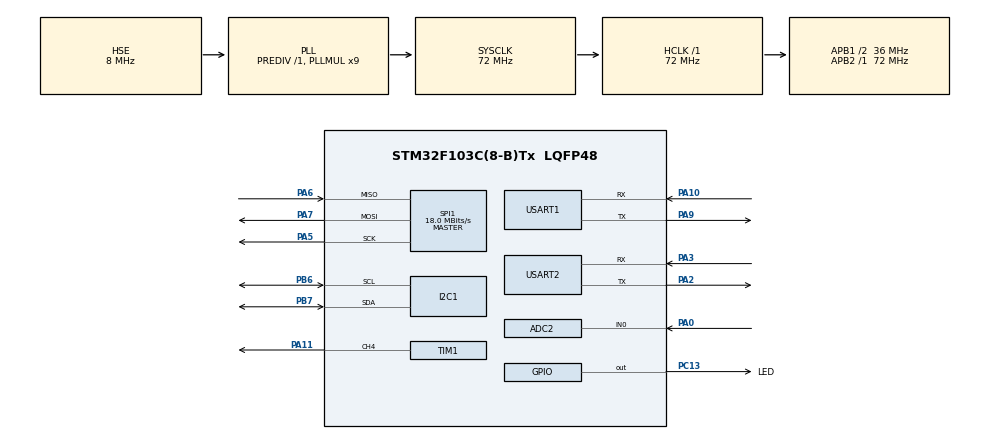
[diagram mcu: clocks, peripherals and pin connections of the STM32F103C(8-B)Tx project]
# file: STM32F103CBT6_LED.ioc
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ADC1.Channel-0\#ChannelRegularConversion=ADC_CHANNEL_TEMPSENSOR
ADC1.ContinuousConvMode=ENABLE
ADC1.NbrOfConversionFlag=1
ADC1.Rank-0\#ChannelRegularConversion=1
ADC1.SamplingTime-0\#ChannelRegularConversion=ADC_SAMPLETIME_239CYCLES_5
ADC1.master=1
ADC2.Channel-0\#ChannelRegularConversion=ADC_CHANNEL_0
ADC2.NbrOfConversionFlag=1
ADC2.Rank-0\#ChannelRegularConversion=1
ADC2.SamplingTime-0\#ChannelRegularConversion=ADC_SAMPLETIME_55CYCLES_5
Dma.MEMTOMEM.0.Direction=DMA_MEMORY_TO_MEMORY
Dma.MEMTOMEM.0.Instance=DMA1_Channel1
Dma.MEMTOMEM.0.MemDataAlignment=DMA_MDATAALIGN_BYTE
Dma.MEMTOMEM.0.MemInc=DMA_MINC_ENABLE
Dma.MEMTOMEM.0.Mode=DMA_NORMAL
Dma.MEMTOMEM.0.PeriphDataAlignment=DMA_PDATAALIGN_BYTE
Dma.MEMTOMEM.0.PeriphInc=DMA_PINC_ENABLE
Dma.MEMTOMEM.0.Priority=DMA_PRIORITY_LOW
Dma.Request0=MEMTOMEM
Dma.Request1=TIM1_CH4/TRIG/COM
Dma.TIM1_CH4/TRIG/COM.1.Direction=DMA_MEMORY_TO_PERIPH
Dma.TIM1_CH4/TRIG/COM.1.Instance=DMA1_Channel4
Dma.TIM1_CH4/TRIG/COM.1.MemDataAlignment=DMA_MDATAALIGN_WORD
Dma.TIM1_CH4/TRIG/COM.1.MemInc=DMA_MINC_ENABLE
Dma.TIM1_CH4/TRIG/COM.1.Mode=DMA_NORMAL
Dma.TIM1_CH4/TRIG/COM.1.PeriphDataAlignment=DMA_PDATAALIGN_WORD
Dma.TIM1_CH4/TRIG/COM.1.PeriphInc=DMA_PINC_DISABLE
Dma.TIM1_CH4/TRIG/COM.1.Priority=DMA_PRIORITY_LOW
IWDG.Prescaler=IWDG_PRESCALER_16
IWDG.Reload=2500-1
Mcu.Family=STM32F1
Mcu.Name=STM32F103C(8-B)Tx
Mcu.Package=LQFP48
NVIC.DMA1_Channel1_IRQn=true\:0\:0\:false\:false\:true\:true\:true\:true
NVIC.DMA1_Channel4_IRQn=true\:0\:0\:false\:false\:true\:false\:true\:true
NVIC.PriorityGroup=NVIC_PRIORITYGROUP_4
PA0-WKUP.Signal=ADCx_IN0
PA10.Mode=Asynchronous
PA10.Signal=USART1_RX
PA11.GPIO_Speed=GPIO_SPEED_FREQ_HIGH
PA11.Signal=S_TIM1_CH4
PA13.Mode=Trace_Asynchronous_SW
PA13.Signal=SYS_JTMS-SWDIO
PA14.Mode=Trace_Asynchronous_SW
PA14.Signal=SYS_JTCK-SWCLK
PA2.Mode=Asynchronous
PA2.Signal=USART2_TX
PA3.Mode=Asynchronous
PA3.Signal=USART2_RX
PA5.Mode=Full_Duplex_Master
PA5.Signal=SPI1_SCK
PA6.Mode=Full_Duplex_Master
PA6.Signal=SPI1_MISO
PA7.Mode=Full_Duplex_Master
PA7.Signal=SPI1_MOSI
PA9.Mode=Asynchronous
PA9.Signal=USART1_TX
PB3.Mode=Trace_Asynchronous_SW
PB3.Signal=SYS_JTDO-TRACESWO
PB6.Mode=I2C
PB6.Signal=I2C1_SCL
PB7.Mode=I2C
PB7.Signal=I2C1_SDA
PC13-TAMPER-RTC.GPIO_Label=LED
PC13-TAMPER-RTC.Signal=GPIO_Output
PD0-OSC_IN.Mode=HSE-External-Oscillator
PD0-OSC_IN.Signal=RCC_OSC_IN
PD1-OSC_OUT.Mode=HSE-External-Oscillator
PD1-OSC_OUT.Signal=RCC_OSC_OUT
ProjectManager.HeapSize=0x200
ProjectManager.StackSize=0x400
ProjectManager.TargetToolchain=STM32CubeIDE
RCC.ADCPresc=RCC_ADCPCLK2_DIV6
RCC.AHBFreq_Value=72000000
RCC.APB1CLKDivider=RCC_HCLK_DIV2
RCC.APB1Freq_Value=36000000
RCC.APB1TimFreq_Value=72000000
RCC.APB2Freq_Value=72000000
RCC.APB2TimFreq_Value=72000000
RCC.HCLKFreq_Value=72000000
RCC.PLLMUL=RCC_PLL_MUL9
RCC.PLLSourceVirtual=RCC_PLLSOURCE_HSE
RCC.SYSCLKFreq_VALUE=72000000
RCC.SYSCLKSource=RCC_SYSCLKSOURCE_PLLCLK
RCC.USBFreq_Value=72000000
SH.ADCx_IN0.0=ADC2_IN0,IN0
SH.S_TIM1_CH4.0=TIM1_CH4,PWM Generation4 CH4
SPI1.BaudRatePrescaler=SPI_BAUDRATEPRESCALER_4
SPI1.CalculateBaudRate=18.0 MBits/s
SPI1.Direction=SPI_DIRECTION_2LINES
SPI1.Mode=SPI_MODE_MASTER
SPI1.VirtualType=VM_MASTER
TIM1.Channel-PWM\ Generation4\ CH4=TIM_CHANNEL_4
TIM1.Period=90-1
TIM1.Prescaler=0
TIM3.Prescaler=72-1
USART1.VirtualMode=VM_ASYNC
USART2.VirtualMode=VM_ASYNC
VP_ADC1_TempSens_Input.Mode=IN-TempSens
VP_CRC_VS_CRC.Mode=CRC_Activate
VP_IWDG_VS_IWDG.Mode=IWDG_Activate
VP_TIM1_VS_ClockSourceINT.Mode=Internal
VP_TIM3_VS_ClockSourceINT.Mode=Internal
board=custom

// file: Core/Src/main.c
/* USER CODE BEGIN Header */
/**
  ******************************************************************************
  * @file           : main.c
  * @brief          : Main program body
  ******************************************************************************
  * @attention
  *
  * Copyright (c) 2026 STMicroelectronics.
  * All rights reserved.
  *
  * This software is licensed under terms that can be found in the LICENSE file
  * in the root directory of this software component.
  * If no LICENSE file comes with this software, it is provided AS-IS.
  *
  ******************************************************************************
  */
/* USER CODE END Header */
#include "main.h"
#include "adc.h"
#include "crc.h"
#include "dma.h"
#include "i2c.h"
#include "iwdg.h"
#include "spi.h"
#include "tim.h"
#include "usart.h"
#include "gpio.h"

/* USER CODE BEGIN Includes */
#include "app_user_task.h"
/* USER CODE END Includes */

void SystemClock_Config(void);

int main(void)
{

  /* MCU Configuration--------------------------------------------------------*/

  /* Reset of all peripherals, Initializes the Flash interface and the Systick. */
  HAL_Init();

  /* Configure the system clock */
  SystemClock_Config();

  /* Initialize all configured peripherals */
  MX_GPIO_Init();
  MX_DMA_Init();
  MX_USART1_UART_Init();
  MX_TIM1_Init();
  //MX_IWDG_Init();
  MX_ADC2_Init();
  MX_ADC1_Init();
  MX_CRC_Init();
  MX_TIM3_Init();
  MX_I2C1_Init();
  MX_SPI1_Init();
  MX_USART2_UART_Init();
  /* USER CODE BEGIN 2 */
  App_User_Task_Init();
  /* USER CODE END 2 */

  /* Infinite loop */
  while (1)
  {

    /* USER CODE BEGIN 3 */
	  App_User_Task();
  }
  /* USER CODE END 3 */
}

void SystemClock_Config(void)
{
  RCC_OscInitTypeDef RCC_OscInitStruct = {0};
  RCC_ClkInitTypeDef RCC_ClkInitStruct = {0};
  RCC_PeriphCLKInitTypeDef PeriphClkInit = {0};

  /** Initializes the RCC Oscillators according to the specified parameters
  * in the RCC_OscInitTypeDef structure.
  */
  RCC_OscInitStruct.OscillatorType = RCC_OSCILLATORTYPE_LSI|RCC_OSCILLATORTYPE_HSE;
  RCC_OscInitStruct.HSEState = RCC_HSE_ON;
  RCC_OscInitStruct.HSEPredivValue = RCC_HSE_PREDIV_DIV1;
  RCC_OscInitStruct.HSIState = RCC_HSI_ON;
  RCC_OscInitStruct.LSIState = RCC_LSI_ON;
  RCC_OscInitStruct.PLL.PLLState = RCC_PLL_ON;
  RCC_OscInitStruct.PLL.PLLSource = RCC_PLLSOURCE_HSE;
  RCC_OscInitStruct.PLL.PLLMUL = RCC_PLL_MUL9;
  if (HAL_RCC_OscConfig(&RCC_OscInitStruct) != HAL_OK)
  {
    Error_Handler();
  }

  /** Initializes the CPU, AHB and APB buses clocks
  */
  RCC_ClkInitStruct.ClockType = RCC_CLOCKTYPE_HCLK|RCC_CLOCKTYPE_SYSCLK
                              |RCC_CLOCKTYPE_PCLK1|RCC_CLOCKTYPE_PCLK2;
  RCC_ClkInitStruct.SYSCLKSource = RCC_SYSCLKSOURCE_PLLCLK;
  RCC_ClkInitStruct.AHBCLKDivider = RCC_SYSCLK_DIV1;
  RCC_ClkInitStruct.APB1CLKDivider = RCC_HCLK_DIV2;
  RCC_ClkInitStruct.APB2CLKDivider = RCC_HCLK_DIV1;

  if (HAL_RCC_ClockConfig(&RCC_ClkInitStruct, FLASH_LATENCY_2) != HAL_OK)
  {
    Error_Handler();
  }
  PeriphClkInit.PeriphClockSelection = RCC_PERIPHCLK_ADC;
  PeriphClkInit.AdcClockSelection = RCC_ADCPCLK2_DIV6;
  if (HAL_RCCEx_PeriphCLKConfig(&PeriphClkInit) != HAL_OK)
  {
    Error_Handler();
  }
}

void Error_Handler(void)
{
  __disable_irq();
  while (1)
  {
  }
}
